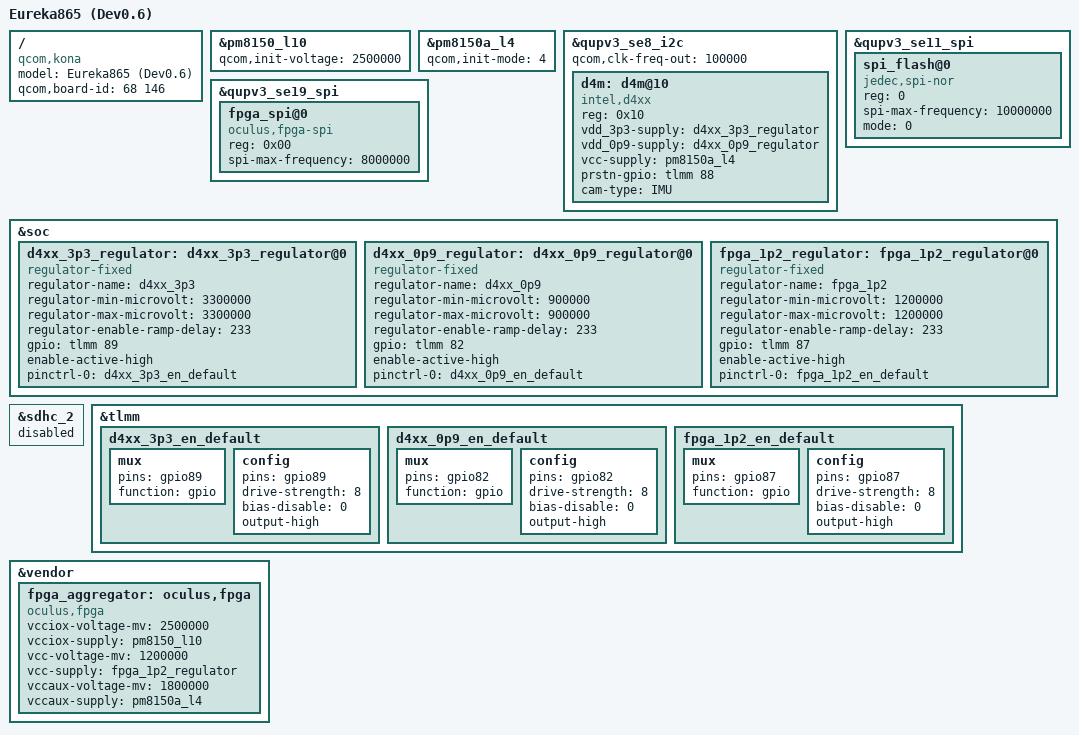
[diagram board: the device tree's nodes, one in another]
// SPDX-License-Identifier: GPL-2.0

/dts-v1/;
/plugin/;

#include "eureka865.dtsi"
#include "eureka865-d4xx-panel.dtsi"

/ {
	model = "Eureka865 (Dev0.6)";
	compatible = "qcom,kona";
	qcom,board-id = <68 146>;
};

&pm8150_l10 {
	qcom,init-voltage = <2500000>;
};

&pm8150a_l4 {
	qcom,init-mode = <4>; /* RPMH_REGULATOR_MODE_HPM */
	status = "ok";
};

&qupv3_se8_i2c {
	status = "ok";
	qcom,clk-freq-out = <100000>;

	d4m: d4m@10 {
		status = "ok";
		reg = <0x10>;
		compatible = "intel,d4xx";
		vdd_3p3-supply = <&d4xx_3p3_regulator>;
		vdd_0p9-supply = <&d4xx_0p9_regulator>;
		vcc-supply = <&pm8150a_l4>;
		prstn-gpio = <&tlmm 88 0>;
		cam-type = "IMU";
	};
};

&qupv3_se11_spi {
	spi_flash@0 {
		#address-cells = <1>;
		#size-cells = <0>;
		compatible = "jedec,spi-nor";
		reg = <0>;
		spi-max-frequency = <10000000>;
		mode = <0>;
		status = "ok";
	};
};

&qupv3_se19_spi {
	status = "ok";

	fpga_spi@0 {
		compatible = "oculus,fpga-spi";
		reg = <0x00>;
		spi-max-frequency = <8000000>;
	};
};

&soc {
	d4xx_3p3_regulator: d4xx_3p3_regulator@0 {
		compatible = "regulator-fixed";
		regulator-name = "d4xx_3p3";
		regulator-min-microvolt = <3300000>;
		regulator-max-microvolt = <3300000>;
		regulator-enable-ramp-delay = <233>;
		gpio = <&tlmm 89 0>;
		enable-active-high;
		pinctrl-names = "default";
		pinctrl-0 = <&d4xx_3p3_en_default>;
	};

	d4xx_0p9_regulator: d4xx_0p9_regulator@0 {
		compatible = "regulator-fixed";
		regulator-name = "d4xx_0p9";
		regulator-min-microvolt = <900000>;
		regulator-max-microvolt = <900000>;
		regulator-enable-ramp-delay = <233>;
		gpio = <&tlmm 82 0>;
		enable-active-high;
		pinctrl-names = "default";
		pinctrl-0 = <&d4xx_0p9_en_default>;
	};

	fpga_1p2_regulator: fpga_1p2_regulator@0 {
		compatible = "regulator-fixed";
		regulator-name = "fpga_1p2";
		regulator-min-microvolt = <1200000>;
		regulator-max-microvolt = <1200000>;
		regulator-enable-ramp-delay = <233>;
		gpio = <&tlmm 87 0>;
		enable-active-high;
		pinctrl-names = "default";
		pinctrl-0 = <&fpga_1p2_en_default>;
	};
};

&sdhc_2 {
	status = "disabled";
};

&tlmm {
	d4xx_3p3_en_default: d4xx_3p3_en_default {
		mux {
			pins = "gpio89";
			function = "gpio";
		};

		config {
			pins = "gpio89";
			drive-strength = <8>;
			bias-disable = <0>;
			output-high;
		};
	};

	d4xx_0p9_en_default: d4xx_0p9_en_default {
		mux {
			pins = "gpio82";
			function = "gpio";
		};

		config {
			pins = "gpio82";
			drive-strength = <8>;
			bias-disable = <0>;
			output-high;
		};
	};

	fpga_1p2_en_default: fpga_1p2_en_default {
		mux {
			pins = "gpio87";
			function = "gpio";
		};

		config {
			pins = "gpio87";
			drive-strength = <8>;
			bias-disable = <0>;
			output-high;
		};
	};
};

&vendor {
	fpga_aggregator: oculus,fpga {
		status = "ok";
		compatible = "oculus,fpga";
		vcciox-voltage-mv = <2500000>;
		vcciox-supply = <&pm8150_l10>;
		vcc-voltage-mv = <1200000>;
		vcc-supply = <&fpga_1p2_regulator>;
		vccaux-voltage-mv = <1800000>;
		vccaux-supply = <&pm8150a_l4>;
	};
};
